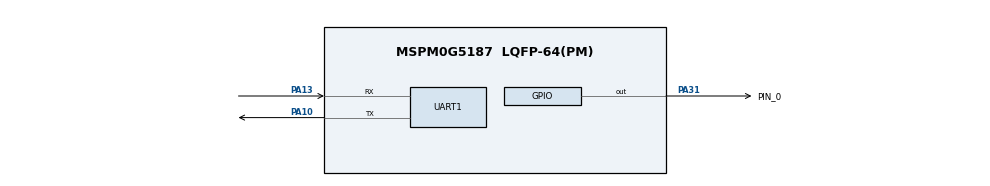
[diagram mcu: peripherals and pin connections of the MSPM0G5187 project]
//@cliArgs --device "MSPM0G518X" --package "LQFP-64(PM)" --part "Default"
//@v2CliArgs --device "MSPM0G5187" --package "LQFP-64(PM)"
// @cliArgs --board /ti/boards/LP_MSPM0G5187 --rtos nortos

/**
 * Import the modules used in this configuration.
 */
const ADC12         = scripting.addModule("/ti/driverlib/ADC12", {}, false);
const ADC121        = ADC12.addInstance();
const GPIO          = scripting.addModule("/ti/driverlib/GPIO", {}, false);
const GPIO1         = GPIO.addInstance();
const SYSCTL        = scripting.addModule("/ti/driverlib/SYSCTL");
const UART          = scripting.addModule("/ti/driverlib/UART", {}, false);
const UART1         = UART.addInstance();
const ProjectConfig = scripting.addModule("/ti/project_config/ProjectConfig");

/**
 * Write custom configuration values to the imported modules.
 */
const divider7       = system.clockTree["PLL_PDIV"];
divider7.divideValue = 2;

const divider9       = system.clockTree["UDIV"];
divider9.divideValue = 2;

const multiplier2         = system.clockTree["PLL_QDIV"];
multiplier2.multiplyValue = 5;

const mux7       = system.clockTree["HSCLKMUX"];
mux7.inputSelect = "HSCLKMUX_SYSPLL2X";

ADC121.$name                            = "ADC12_0";
ADC121.repeatMode                       = true;
ADC121.adcMem0chansel                   = "DL_ADC12_INPUT_CHAN_8";
ADC121.powerDownMode                    = "DL_ADC12_POWER_DOWN_MODE_MANUAL";
ADC121.hwNumerator                      = "DL_ADC12_HW_AVG_NUM_ACC_4";
ADC121.enabledInterrupts                = ["DL_ADC12_INTERRUPT_DMA_DONE"];
ADC121.configureDMA                     = true;
ADC121.enableFIFO                       = true;
ADC121.sampleTime0                      = "9.3 us";
ADC121.sampCnt                          = 6;
ADC121.enabledDMATriggers               = ["DL_ADC12_DMA_MEM11_RESULT_LOADED"];
ADC121.peripheral.$assign               = "ADC0";
ADC121.peripheral.adcPin8.$assign       = "PA21";
ADC121.DMA_CHANNEL.addressMode          = "f2b";
ADC121.DMA_CHANNEL.enableInterrupt      = true;
ADC121.DMA_CHANNEL.earlyIntThresh       = "HALF";
ADC121.DMA_CHANNEL.enableEarlyInterrupt = true;
ADC121.DMA_CHANNEL.$name                = "DMA_CH2";
ADC121.DMA_CHANNEL.peripheral.$assign   = "DMA_CH2";

const Board = scripting.addModule("/ti/driverlib/Board", {}, false);

GPIO1.$name                         = "GPIO_GRP_0";
GPIO1.associatedPins[0].$name       = "PIN_0";
GPIO1.associatedPins[0].pin.$assign = "PA31";

SYSCTL.forceDefaultClkConfig = true;
SYSCTL.clockTreeEn           = true;

UART1.enableFIFO                        = true;
UART1.rxFifoThreshold                   = "DL_UART_RX_FIFO_LEVEL_ONE_ENTRY";
UART1.txFifoThreshold                   = "DL_UART_TX_FIFO_LEVEL_3_4_EMPTY";
UART1.enabledDMARXTriggers              = "DL_UART_DMA_INTERRUPT_RX";
UART1.enabledDMATXTriggers              = "DL_UART_DMA_INTERRUPT_TX";
UART1.$name                             = "UART_DAP";
UART1.targetBaudRate                    = 5820000;
UART1.ovsRate                           = "8";
UART1.peripheral.$assign                = "UC3";
UART1.peripheral.rxPin.$assign          = "PA13";
UART1.peripheral.txPin.$assign          = "PA10";
UART1.DMA_CHANNEL_RX.$name              = "DMA_CH0";
UART1.DMA_CHANNEL_RX.addressMode        = "f2b";
UART1.DMA_CHANNEL_RX.srcLength          = "BYTE";
UART1.DMA_CHANNEL_RX.dstLength          = "BYTE";
UART1.DMA_CHANNEL_RX.peripheral.$assign = "DMA_CH0";
UART1.DMA_CHANNEL_TX.$name              = "DMA_CH1";
UART1.DMA_CHANNEL_TX.addressMode        = "b2f";
UART1.DMA_CHANNEL_TX.srcLength          = "BYTE";
UART1.DMA_CHANNEL_TX.dstLength          = "BYTE";
UART1.DMA_CHANNEL_TX.enableInterrupt    = true;
UART1.DMA_CHANNEL_TX.peripheral.$assign = "DMA_CH1";

ProjectConfig.migrationCondition = true;
ProjectConfig.genLibNPU          = true;
ProjectConfig.genLibCMSIS        = true;
